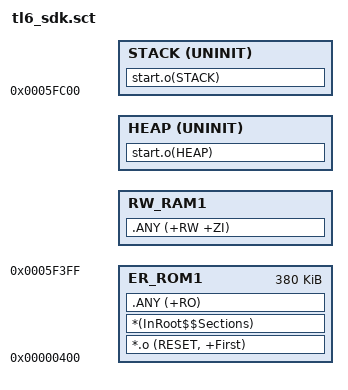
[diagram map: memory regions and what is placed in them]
; *************************************************************
; *** Scatter-Loading Description File generated by uVision ***
; *************************************************************

LR_ROM1 0x0000400 0x005F000  {    ; load region size_region
  ER_ROM1 0x000400 0x0005F000  {  ; load address = execution address
   *.o (RESET, +First)
   *(InRoot$$Sections)
   .ANY (+RO)
  }
  RW_RAM1 +0   {  ; RW data
   .ANY (+RW +ZI)
  }

  HEAP +0 UNINIT
  {
  	start.o(HEAP)
  }

  STACK 0x5FC00 UNINIT
  {
    start.o(STACK)
  }
}
ScatterAssert(ImageLength(LR_ROM1) < 0x60000)
